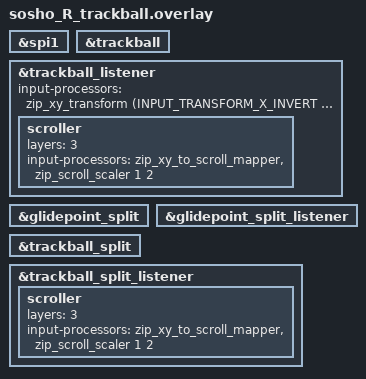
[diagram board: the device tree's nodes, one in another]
#include "sosho_R.dtsi"

&spi1 { status = "okay"; };
&trackball { status = "okay"; };
&trackball_listener {
	status = "okay";
	input-processors = <&zip_xy_transform (INPUT_TRANSFORM_X_INVERT | INPUT_TRANSFORM_Y_INVERT)>;
	// レイヤー3が有効なとき、トラックボールのXY移動をスクロールに変換します。
	// スクロール速度は &zip_scroll_scaler の multiplier / divisor で調整します。
	// 例: <&zip_scroll_scaler 1 2 &zip_xy_to_scroll_mapper> は半分の速度、
	//      <&zip_scroll_scaler 2 1 &zip_xy_to_scroll_mapper> は倍速です。
	scroller {
		layers = <3>;
		input-processors = <&zip_xy_to_scroll_mapper &zip_scroll_scaler 1 2>;
	};
};

&glidepoint_split { status = "okay"; };
&glidepoint_split_listener {
    status = "okay";
/* input-processors = <&zip_xy_scaler 2 1>; */
};

&trackball_split { status = "okay"; };
&trackball_split_listener {
    status = "okay";
    // split input 版のトラックボールも同様にレイヤー3時スクロールに変換します。
    // multiplier/divisor を変更するとスクロール速度を細かく調整できます。
    // 例: 1 2 で半分、2 1 で2倍です。
    scroller {
        layers = <3>;
        input-processors = <&zip_xy_to_scroll_mapper &zip_scroll_scaler 1 2>;
    };
};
